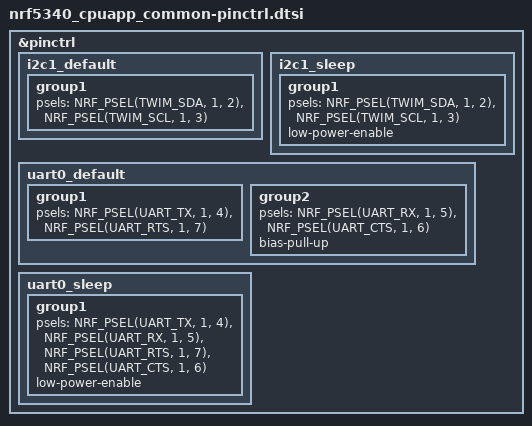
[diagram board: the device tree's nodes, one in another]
/*
 * Copyright (c) 2022 Nordic Semiconductor
 * SPDX-License-Identifier: Apache-2.0
 */

&pinctrl {
	i2c1_default: i2c1_default {
		group1 {
			psels = <NRF_PSEL(TWIM_SDA, 1, 2)>,
				<NRF_PSEL(TWIM_SCL, 1, 3)>;
		};
	};

	i2c1_sleep: i2c1_sleep {
		group1 {
			psels = <NRF_PSEL(TWIM_SDA, 1, 2)>,
				<NRF_PSEL(TWIM_SCL, 1, 3)>;
			low-power-enable;
		};
	};

	uart0_default: uart0_default {
		group1 {
			psels = <NRF_PSEL(UART_TX, 1, 4)>,
				<NRF_PSEL(UART_RTS, 1, 7)>;
		};
		group2 {
			psels = <NRF_PSEL(UART_RX, 1, 5)>,
				<NRF_PSEL(UART_CTS, 1, 6)>;
			bias-pull-up;
		};
	};

	uart0_sleep: uart0_sleep {
		group1 {
			psels = <NRF_PSEL(UART_TX, 1, 4)>,
				<NRF_PSEL(UART_RX, 1, 5)>,
				<NRF_PSEL(UART_RTS, 1, 7)>,
				<NRF_PSEL(UART_CTS, 1, 6)>;
			low-power-enable;
		};
	};

};
